# CC2340R5 register map
File version: 1.0
CPU: CM0P 1.0, other endian, MPU, FPU, 3 interrupt priority bits
Registers are 32-bit, read-write, reset 0x0 unless marked. A register's access mark holds for its fields unless they carry their own. Offsets are from the block's base; [hi:lo] are bit positions.

## I2C0 — I2C IP
Base 0x40038000
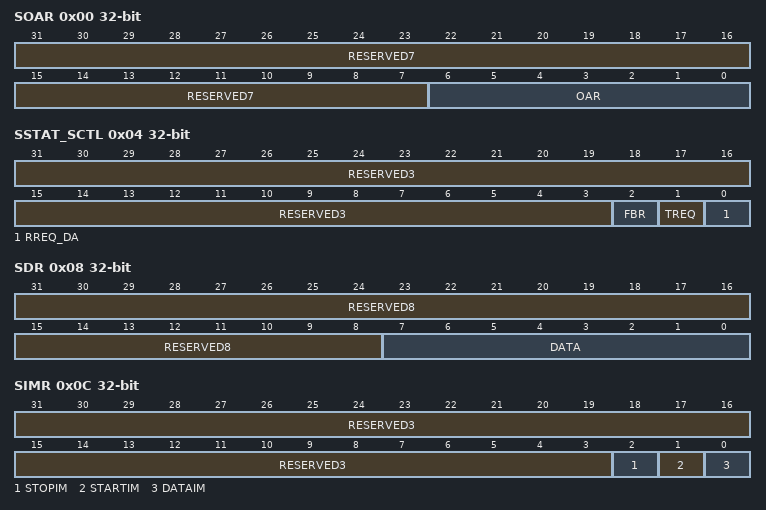
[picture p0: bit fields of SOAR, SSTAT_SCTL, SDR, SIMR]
0x00 SOAR — Slave Own Address This register consists of seven address bits that identify this I2C device on the I2C bus.
  [31:7] RESERVED7 ro — [31:7] Reads to this field return zero.Writes to this field are ignored.
  [6:0] OAR — [6:0] I2C slave own address. This field specifies bits a6 through a0 of the slave address.
0x04 SSTAT_SCTL — Slave Control and Slave Status This register functions as a control register when written, and a status register when read.
  [31:3] RESERVED3 ro — [31:3] Reads to this field return zero.Writes to this field are ignored.
  [2] FBR ro — [2:2] First byte received. 0 - The first byte following the slave's own address has not been received. 1 - The first byte following the slave's own address has been received. This bit is only valide when the RREQ bit is set and is automatically cleared when data has been read from the SDR register. Note: This bit is not used for slave transmit operations.
  [1] TREQ ro — [1:1] Transmit request 0 - No outstanding transmit request 1 - The *I2C* controller has been addressed as a slave transmitter and is using clock stretching to delay the master until data has been written to the SDR register.
  [0] RREQ_DA — [0:0] This field reflects the Receive Request status when read and sets the Device Active control when written. When read: 0 - No outstanding receive data 1 - The *I2C* controller has outstanding receive data from the *I2C* master and is using clock stretching to delay the master until data has been read from the SDR register When written: 0 - Disables the *I2C* slave operation 1 - Enables the *I2C* slave operation
0x08 SDR — Slave Data This register contains the data to be transmitted when in the Slave Transmit state, and the data received when in the Slave Receive state.
  [31:8] RESERVED8 ro — [31:8] Reads to this field return zero.Writes to this field are ignored.
  [7:0] DATA — [7:0] Data for transfer. This field contains the data for transfer during a slave receive or a transmit operation. When written the register data is used as transmit data When read, this register returns the last data received. Data is stored until next update, either by a system write to the master for transmit or by an external master to the slave for receive.
0x0C SIMR — Slave Interrupt Mask This register controls whether a raw interrupt is promoted to a controller interrupt.
  [31:3] RESERVED3 ro — [31:3] Reads to this field return zero.Writes to this field are ignored.
  [2] STOPIM — [2:2] Stop condition interrupt mask
    1=ENA (ENA interrupt mask); 0=DIS (DIS interrupt mask)
  [1] STARTIM — [1:1] Start condition interrupt mask
    1=ENA (ENA Interrupt Mask); 0=DIS (Disable Interrupt Mask)
  [0] DATAIM — [0:0] Data interrupt mask
    1=ENA (ENA interrupt mask); 0=DIS (DIS interrupt mask)
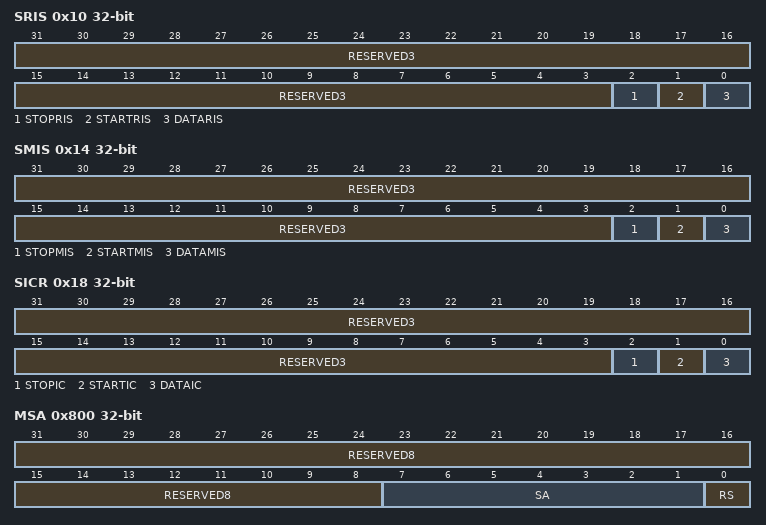
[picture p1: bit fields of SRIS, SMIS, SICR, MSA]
0x10 SRIS — Slave Raw Interrupt Status This register shows the unmasked interrupt status.
  [31:3] RESERVED3 ro — [31:3] Reads to this field return zero.Writes to this field are ignored.
  [2] STOPRIS ro — [2:2] Stop condition raw interrupt status 0 - Interrupt did not occur 1 - Interrupt occured This bit is cleared by writing a 1 to SICR.STOPIC.
  [1] STARTRIS ro — [1:1] Start condition raw interrupt status 0 - Interrupt did not occur 1 - Interrupt occured This bit is cleared by writing a 1 to SICR.STARTIC.
  [0] DATARIS ro — [0:0] Data raw interrupt status 0 - Interrupt did not occur 1 - Interrupt occured This bit is cleared by writing a 1 to the SICR.DATAIC.
0x14 SMIS — Slave Masked Interrupt Status This register show which interrupt is active (based on result from SRIS and SIMR).
  [31:3] RESERVED3 ro — [31:3] Reads to this field return zero.Writes to this field are ignored.
  [2] STOPMIS ro — [2:2] Stop condition masked interrupt status 0 - Interrupt did not occur 1 - Interrupt occured This bit is cleared by writing a 1 to the SICR.STOPIC.
  [1] STARTMIS ro — [1:1] Start condition masked interrupt status 0 - Interrupt did not occur 1 - Interrupt occured This bit is cleared by writing a 1 to the SICR.STARTIC.
  [0] DATAMIS ro — [0:0] Start condition masked interrupt status 0 - Interrupt did not occur 1 - Interrupt occured This bit is cleared by writing a 1 to the SICR.STARTIC.
0x18 SICR — Slave Interrupt Clear This register clears the raw interrupt SRIS.
  [31:3] RESERVED3 ro — [31:3] Reads to this field return zero.Writes to this field are ignored.
  [2] STOPIC wo — [2:2] Stop condition interrupt clear 0 - Writing 0 has no effect 1 - Set interrupt Writing 1 to this bit clears SRIS.STOPRIS and SMIS.STOPMIS.
  [1] STARTIC wo — [1:1] Start condition interrupt clear 0 - Writing 0 has no effect 1 - Set interrupt Writing 1 to this bit clears SRIS.STARTRIS and SMIS.STARTMIS.
  [0] DATAIC wo — [0:0] Data interrupt clear 0 - Writing 0 has no effect 1 - Set interrupt Writing 1 to this bit clears SRIS.DATARIS and SMIS.DATAMIS.
0x800 MSA — Master Slave Address This register contains seven address bits of the slave to be accessed by the master (a6-a0), and an RS bit determining if the next operation is a receive or transmit.
  [31:8] RESERVED8 ro — [31:8] Reads to this field return zero.Writes to this field are ignored.
  [7:1] SA — [7:1] *I2C* master slave address Defines which slave is addressed for the transaction in master mode
  [0] RS — [0:0] Receive or Send This bit-field specifies the next operation with addressed slave SA. 0 - Transmit/send data to slave 1 - Receive data from slave
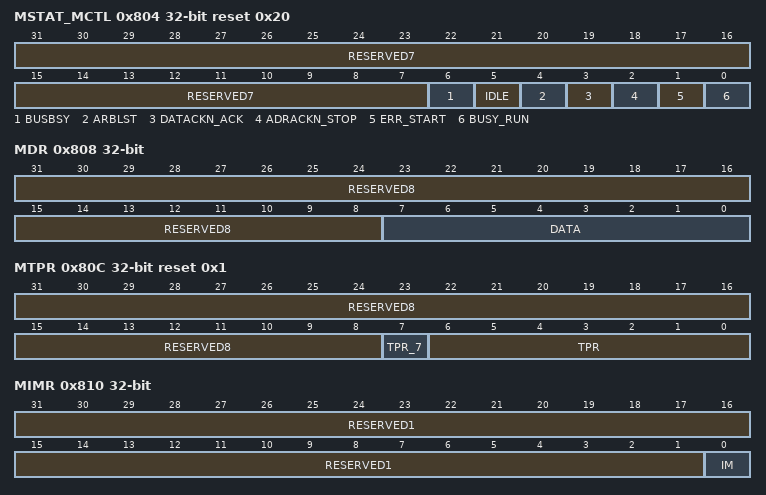
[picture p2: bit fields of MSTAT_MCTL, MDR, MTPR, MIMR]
0x804 MSTAT_MCTL reset 0x20 — Master Control and Status This register functions as a control register when written, and a status register when read.
  [31:7] RESERVED7 ro — [31:7] Reads to this field return zero.Writes to this field are ignored.
  [6] BUSBSY ro — [6:6] Bus busy 0 - The *I2C* bus is idle. 1 - The *I2C* bus is busy. Note:The bit changes based on the MCTRL.START and MCTRL.STOP conditions.
  [5] IDLE ro — [5:5] *I2C* idle 0 - The *I2C* controller is not idle. 1 - The *I2C* controller is idle.
  [4] ARBLST ro — [4:4] Arbitration status 0 - The *I2C* controller won arbitration. 1 - The *I2C* controller lost arbitration.
  [3] DATACKN_ACK — [3:3] This field contains Data acknowledge in status read and Data acknowledge enable in control write. Status Read: Data Acknowledge 0 - The transmitted data was acknowledged. 1 - The transmitted data was not acknowledged. Control write: Data acknowledge enable 0 - The received data byte is not acknowledged automatically by the master. 1 - The received data byte is acknowledged automatically by the master. Note:This bit-field must be cleared when the I2C bus controller requires no further data to be transmitted from the slave transmitter.
  [2] ADRACKN_STOP — [2:2] This field reflects the address acknowledge status when read and sets stop condition when written. When read: 0 - The transmitted address was acknowledged. 1 - The transmitted address was not acknowledged. When written Note:This bit-field determines if the cycle stops at the end of the data cycle or continues on to a repeated START condition. 0 - The controller does not generate the Stop condition. 1 - The controller generates the Stop condition.
  [1] ERR_START — [1:1] This field reflect the error status when read and sets start or repeated start condition when written. When read: 0 - No error was detected on the last operation. 1 - An error occurred on the last operation. When written: 0 - The controller does not generate the Start condition. 1 - The controller generates the Start condition.
  [0] BUSY_RUN — [0:0] This field reflects the *I2C* busy status when read and sets *I2C* master enable when written. When Read 0 - The controller is idle. 1 - The controller is busy. When this bit-field is set, the other status bits are not valid. Note: The *I2C* controller requires four SYSBUS clock cycles to assert the BUSY status after *I2C* master operation has been initiated through a write into MSTAT_MCTL register. Hence after programming MCTRL register, application is requested to wait for four SYSBUS clock cycles before issuing a controller status inquiry through a read from MSTAT_MCTL register. Any prior inquiry would result in wrong status being reported. When written: 0 - The master is disabled. 1 - The master is enabled to transmit or receive data.
0x808 MDR — Master Data This register contains the data to be transmitted when in the Master Transmit state and the data received when in the Master Receive state.
  [31:8] RESERVED8 ro — [31:8] Reads to this field return zero.Writes to this field are ignored.
  [7:0] DATA — [7:0] When Read: Last RX Data is returned When Written: Data is transferred during TX transaction
0x80C MTPR reset 0x1 — Master Timer Period This register specifies the period of the SCL clock.
  [31:8] RESERVED8 ro — [31:8] Reads to this field return zero.Writes to this field are ignored.
  [7] TPR_7 — [7:7] Must be set to 0 to set TPR. If set to 1, a write to TPR will be ignored.
  [6:0] TPR — [6:0] SCL clock period This field specifies the period of the SCL clock. SCL_PRD = 2*(1+TPR)*(SCL_LP + SCL_HP)*CLK_PRD, where: SCL_PRD is the SCL line period (I2C clock). TPR is the timer period register value (range of 1 to 127) SCL_LP is the SCL low period (fixed at 6). SCL_HP is the SCL high period (fixed at 4). CLK_PRD is the system clock period in ns.
0x810 MIMR — Master Interrupt Mask This register controls whether a raw interrupt is promoted to a controller interrupt.
  [31:1] RESERVED1 ro — [31:1] Reads to this field return zero.Writes to this field are ignored.
  [0] IM — [0:0] Interrupt mask
    1=ENA (ENA Interrupt mask); 0=DIS (Disable Interrupt mask)
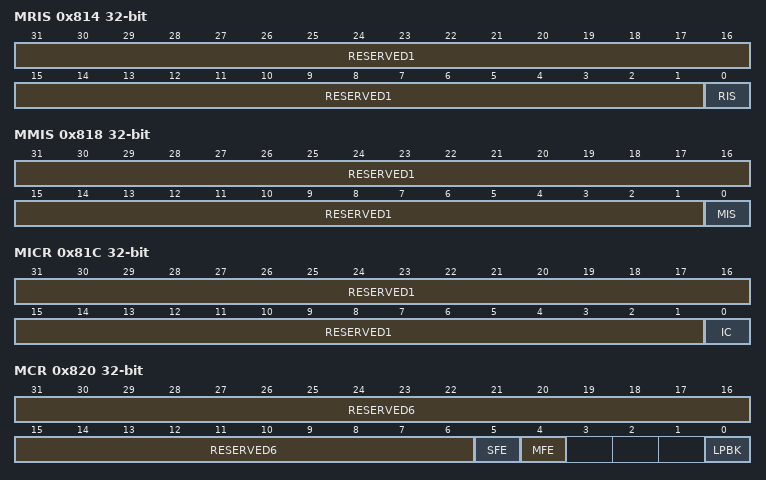
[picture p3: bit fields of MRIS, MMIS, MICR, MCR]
0x814 MRIS — Master Raw Interrupt Status This register show the unmasked interrupt status.
  [31:1] RESERVED1 ro — [31:1] Reads to this field return zero.Writes to this field are ignored.
  [0] RIS ro — [0:0] Raw interrupt status 0 - Interrupt did not occur 1 - Interrupt occured This bit is cleared by writing 1 to the MICR.IC bit.
0x818 MMIS — Master Masked Interrupt Status This register show which interrupt is active (based on result from MRIS and MIMR).
  [31:1] RESERVED1 ro — [31:1] Reads to this field return zero.Writes to this field are ignored.
  [0] MIS ro — [0:0] Masked interrupt status 0 - Interrupt did not occur 1 - Interrupt occured This bit is cleared by writing 1 to the MICR.IC bit.
0x81C MICR — Master Interrupt Clear This register clears the raw and masked interrupt.
  [31:1] RESERVED1 ro — [31:1] Reads to this field return zero.Writes to this field are ignored.
  [0] IC wo — [0:0] Interrupt clear 0 - Writing 0 has no effect 1 - Clear Interrupt Writing 1 to this bit clears MRIS.RIS and MMIS.MIS.
0x820 MCR — Master Configuration This register configures the mode (Master or Slave) and sets the interface for test mode loopback.
  [31:6] RESERVED6 ro — [31:6] Reads to this field return zero.Writes to this field are ignored.
  [5] SFE — [5:5] I2C slave function enable
    1=ENA (Slave mode enabled); 0=DIS (Slave mode disabled)
  [4] MFE — [4:4] I2C master function enable
    1=ENA (Master mode enabled); 0=DIS (Master mode disabled)
  [0] LPBK — [0:0] I2C loopback
    1=ENA (Test mode(Loopback operation) enabled); 0=DIS (Test mode(Loopback operation) disabled)
